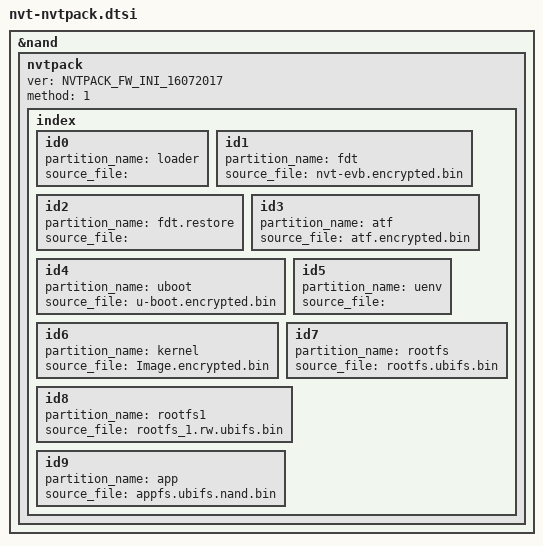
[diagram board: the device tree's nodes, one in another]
/*
 * Novatek Ltd. BSP part of dts
 */

&nand {
	nvtpack {
		ver = "NVTPACK_FW_INI_16072017"; /* Fixed */
		method = <1>; /* Fixed */
		index {
			id0 { partition_name = "loader";      source_file = ""; }; /* Fixed */
			id1 { partition_name = "fdt";         source_file = "nvt-evb.encrypted.bin"; }; /* Fixed */
			id2 { partition_name = "fdt.restore"; source_file = "";	}; /* Fixed */
			id3 { partition_name = "atf";         source_file = "atf.encrypted.bin"; };
			id4 { partition_name = "uboot";	      source_file = "u-boot.encrypted.bin"; };
			id5 { partition_name = "uenv";	      source_file = ""; };
			id6 { partition_name = "kernel";      source_file = "Image.encrypted.bin"; };
			id7 { partition_name = "rootfs";      source_file = "rootfs.ubifs.bin"; };
			id8 { partition_name = "rootfs1";     source_file = "rootfs_1.rw.ubifs.bin"; };
			id9 { partition_name = "app";         source_file = "appfs.ubifs.nand.bin"; };
		};
	};
};
